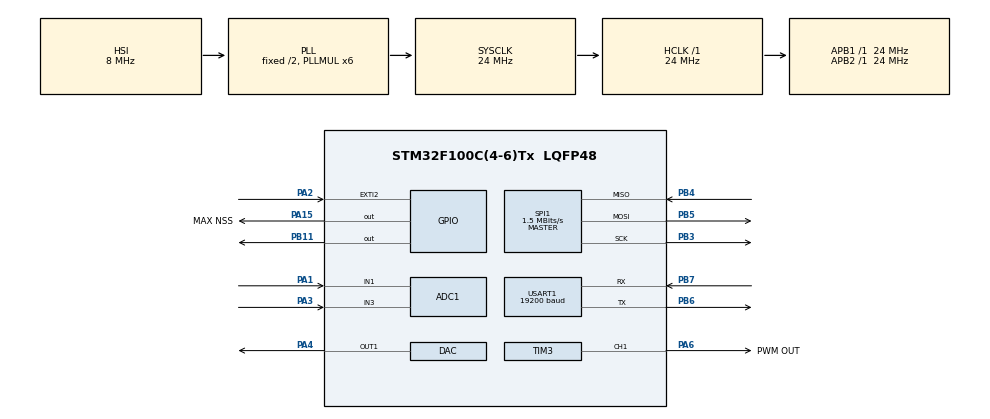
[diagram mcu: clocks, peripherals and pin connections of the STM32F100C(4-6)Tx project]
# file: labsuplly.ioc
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ADC1.Channel-17\#ChannelRegularConversion=ADC_CHANNEL_1
ADC1.Channel-18\#ChannelRegularConversion=ADC_CHANNEL_3
ADC1.ContinuousConvMode=ENABLE
ADC1.DataAlign=ADC_DATAALIGN_RIGHT
ADC1.DiscontinuousConvMode=DISABLE
ADC1.EnableAnalogWatchDog=false
ADC1.EnableRegularConversion=ENABLE
ADC1.ExternalTrigConvEdgeChoice=NONE
ADC1.InjNumberOfConversion=0
ADC1.NbrOfConversion=2
ADC1.NbrOfConversionFlag=1
ADC1.Rank-17\#ChannelRegularConversion=1
ADC1.Rank-18\#ChannelRegularConversion=2
ADC1.SamplingTime-17\#ChannelRegularConversion=ADC_SAMPLETIME_1CYCLE_5
ADC1.SamplingTime-18\#ChannelRegularConversion=ADC_SAMPLETIME_7CYCLES_5
ADC1.ScanConvMode=ADC_SCAN_ENABLE
ADC1.master=1
DAC.DAC_OutputBuffer=DAC_OUTPUTBUFFER_DISABLE
Dma.ADC1.0.Direction=DMA_PERIPH_TO_MEMORY
Dma.ADC1.0.Instance=DMA1_Channel1
Dma.ADC1.0.MemDataAlignment=DMA_MDATAALIGN_WORD
Dma.ADC1.0.MemInc=DMA_MINC_ENABLE
Dma.ADC1.0.Mode=DMA_NORMAL
Dma.ADC1.0.PeriphDataAlignment=DMA_PDATAALIGN_WORD
Dma.ADC1.0.PeriphInc=DMA_PINC_DISABLE
Dma.ADC1.0.Priority=DMA_PRIORITY_MEDIUM
Dma.Request0=ADC1
Dma.Request1=USART1_RX
Dma.Request2=USART1_TX
Dma.USART1_RX.1.Direction=DMA_PERIPH_TO_MEMORY
Dma.USART1_RX.1.Instance=DMA1_Channel5
Dma.USART1_RX.1.MemDataAlignment=DMA_MDATAALIGN_BYTE
Dma.USART1_RX.1.MemInc=DMA_MINC_ENABLE
Dma.USART1_RX.1.Mode=DMA_NORMAL
Dma.USART1_RX.1.PeriphDataAlignment=DMA_PDATAALIGN_BYTE
Dma.USART1_RX.1.PeriphInc=DMA_PINC_DISABLE
Dma.USART1_RX.1.Priority=DMA_PRIORITY_LOW
Dma.USART1_TX.2.Direction=DMA_MEMORY_TO_PERIPH
Dma.USART1_TX.2.Instance=DMA1_Channel4
Dma.USART1_TX.2.MemDataAlignment=DMA_MDATAALIGN_BYTE
Dma.USART1_TX.2.MemInc=DMA_MINC_ENABLE
Dma.USART1_TX.2.Mode=DMA_NORMAL
Dma.USART1_TX.2.PeriphDataAlignment=DMA_PDATAALIGN_BYTE
Dma.USART1_TX.2.PeriphInc=DMA_PINC_DISABLE
Dma.USART1_TX.2.Priority=DMA_PRIORITY_LOW
Mcu.Family=STM32F1
Mcu.Name=STM32F100C(4-6)Tx
Mcu.Package=LQFP48
NVIC.DMA1_Channel1_IRQn=true\:12\:0\:true\:false\:true
NVIC.DMA1_Channel4_IRQn=true\:13\:0\:true\:false\:true
NVIC.DMA1_Channel5_IRQn=true\:14\:0\:true\:false\:true
NVIC.EXTI2_IRQn=true\:1\:0\:true\:false\:true
NVIC.PriorityGroup=NVIC_PRIORITYGROUP_4
NVIC.SPI1_IRQn=true\:10\:0\:true\:false\:true
NVIC.TIM2_IRQn=true\:11\:0\:true\:false\:true
PA1.Signal=ADCx_IN1
PA13.Mode=Serial_Wire
PA13.Signal=SYS_JTMS-SWDIO
PA14.Mode=Serial_Wire
PA14.Signal=SYS_JTCK-SWCLK
PA15.GPIO_Label=MAX NSS
PA15.GPIO_Speed=GPIO_SPEED_FREQ_MEDIUM
PA15.PinState=GPIO_PIN_SET
PA15.Signal=GPIO_Output
PA2.GPIO_PuPd=GPIO_PULLUP
PA2.Signal=GPXTI2
PA3.Signal=ADCx_IN3
PA4.Signal=COMP_DAC1_group
PA6.GPIO_Label=PWM OUT
PA6.GPIO_Speed=GPIO_SPEED_FREQ_LOW
PA6.Signal=S_TIM3_CH1
PB11.GPIO_ModeDefaultOutputPP=GPIO_MODE_OUTPUT_OD
PB11.PinState=GPIO_PIN_SET
PB11.Signal=GPIO_Output
PB3.GPIO_Speed=GPIO_SPEED_FREQ_LOW
PB3.Mode=Full_Duplex_Master
PB3.Signal=SPI1_SCK
PB4.GPIO_PuPd=GPIO_PULLDOWN
PB4.Mode=Full_Duplex_Master
PB4.Signal=SPI1_MISO
PB5.GPIO_Speed=GPIO_SPEED_FREQ_LOW
PB5.Mode=Full_Duplex_Master
PB5.Signal=SPI1_MOSI
PB6.Mode=Asynchronous
PB6.Signal=USART1_TX
PB7.GPIO_PuPd=GPIO_PULLUP
PB7.Mode=Asynchronous
PB7.Signal=USART1_RX
ProjectManager.HeapSize=0x200
ProjectManager.StackSize=0x400
ProjectManager.TargetToolchain=TrueSTUDIO
RCC.AHBFreq_Value=24000000
RCC.APB1Freq_Value=24000000
RCC.APB1TimFreq_Value=24000000
RCC.APB2Freq_Value=24000000
RCC.APB2TimFreq_Value=24000000
RCC.HCLKFreq_Value=24000000
RCC.PLLMUL=RCC_PLL_MUL6
RCC.SYSCLKFreq_VALUE=24000000
RCC.SYSCLKSource=RCC_SYSCLKSOURCE_PLLCLK
SH.ADCx_IN1.0=ADC1_IN1,IN1
SH.ADCx_IN3.0=ADC1_IN3,IN3
SH.COMP_DAC1_group.0=DAC_OUT1,DAC_OUT1
SH.S_TIM3_CH1.0=TIM3_CH1,PWM Generation1 CH1
SPI1.BaudRatePrescaler=SPI_BAUDRATEPRESCALER_16
SPI1.CalculateBaudRate=1.5 MBits/s
SPI1.DataSize=SPI_DATASIZE_16BIT
SPI1.Mode=SPI_MODE_MASTER
TIM2.Period=2399
TIM2.Prescaler=9
TIM3.Period=3399
USART1.BaudRate=19200
VP_TIM2_VS_ClockSourceINT.Mode=Internal
VP_TIM3_VS_ClockSourceINT.Mode=Internal
board=labsuplly

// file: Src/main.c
/**
  ******************************************************************************
  * File Name          : main.c
  * Description        : Main program body
  ******************************************************************************
  *
  * COPYRIGHT(c) 2016 STMicroelectronics
  *
  * Redistribution and use in source and binary forms, with or without modification,
  * are permitted provided that the following conditions are met:
  *   1. Redistributions of source code must retain the above copyright notice,
  *      this list of conditions and the following disclaimer.
  *   2. Redistributions in binary form must reproduce the above copyright notice,
  *      this list of conditions and the following disclaimer in the documentation
  *      and/or other materials provided with the distribution.
  *   3. Neither the name of STMicroelectronics nor the names of its contributors
  *      may be used to endorse or promote products derived from this software
  *      without specific prior written permission.
  *
  * THIS SOFTWARE IS PROVIDED BY THE COPYRIGHT HOLDERS AND CONTRIBUTORS "AS IS"
  * AND ANY EXPRESS OR IMPLIED WARRANTIES, INCLUDING, BUT NOT LIMITED TO, THE
  * IMPLIED WARRANTIES OF MERCHANTABILITY AND FITNESS FOR A PARTICULAR PURPOSE ARE
  * DISCLAIMED. IN NO EVENT SHALL THE COPYRIGHT HOLDER OR CONTRIBUTORS BE LIABLE
  * FOR ANY DIRECT, INDIRECT, INCIDENTAL, SPECIAL, EXEMPLARY, OR CONSEQUENTIAL
  * DAMAGES (INCLUDING, BUT NOT LIMITED TO, PROCUREMENT OF SUBSTITUTE GOODS OR
  * SERVICES; LOSS OF USE, DATA, OR PROFITS; OR BUSINESS INTERRUPTION) HOWEVER
  * CAUSED AND ON ANY THEORY OF LIABILITY, WHETHER IN CONTRACT, STRICT LIABILITY,
  * OR TORT (INCLUDING NEGLIGENCE OR OTHERWISE) ARISING IN ANY WAY OUT OF THE USE
  * OF THIS SOFTWARE, EVEN IF ADVISED OF THE POSSIBILITY OF SUCH DAMAGE.
  *
  ******************************************************************************
  */
#include "stm32f1xx_hal.h"
#include "adc.h"
#include "dac.h"
#include "dma.h"
#include "spi.h"
#include "tim.h"
#include "usart.h"
#include "gpio.h"

void SystemClock_Config(void);

/* USER CODE BEGIN PFP */
/* Private function prototypes -----------------------------------------------*/

/* USER CODE END PFP */

int main(void)
{

  /* MCU Configuration----------------------------------------------------------*/

  /* Reset of all peripherals, Initializes the Flash interface and the Systick. */
  HAL_Init();

  /* Configure the system clock */
  SystemClock_Config();

  /* Initialize all configured peripherals */
  MX_GPIO_Init();
  MX_DMA_Init();
  MX_TIM3_Init();
  MX_ADC1_Init();
  MX_SPI1_Init();
  MX_TIM2_Init();
  MX_USART1_UART_Init();
  MX_DAC_Init();

  /* Infinite loop */
  while (1)
  {

  /* USER CODE BEGIN 3 */

	  ApplicationMain();
	  //user code
  }
  /* USER CODE END 3 */

}

/** System Clock Configuration
*/
void SystemClock_Config(void)
{

  RCC_OscInitTypeDef RCC_OscInitStruct;
  RCC_ClkInitTypeDef RCC_ClkInitStruct;
  RCC_PeriphCLKInitTypeDef PeriphClkInit;

  RCC_OscInitStruct.OscillatorType = RCC_OSCILLATORTYPE_HSI;
  RCC_OscInitStruct.HSIState = RCC_HSI_ON;
  RCC_OscInitStruct.HSICalibrationValue = 16;
  RCC_OscInitStruct.PLL.PLLState = RCC_PLL_ON;
  RCC_OscInitStruct.PLL.PLLSource = RCC_PLLSOURCE_HSI_DIV2;
  RCC_OscInitStruct.PLL.PLLMUL = RCC_PLL_MUL6;
  HAL_RCC_OscConfig(&RCC_OscInitStruct);

  RCC_ClkInitStruct.ClockType = RCC_CLOCKTYPE_HCLK|RCC_CLOCKTYPE_SYSCLK
                              |RCC_CLOCKTYPE_PCLK1|RCC_CLOCKTYPE_PCLK2;
  RCC_ClkInitStruct.SYSCLKSource = RCC_SYSCLKSOURCE_PLLCLK;
  RCC_ClkInitStruct.AHBCLKDivider = RCC_SYSCLK_DIV1;
  RCC_ClkInitStruct.APB1CLKDivider = RCC_HCLK_DIV1;
  RCC_ClkInitStruct.APB2CLKDivider = RCC_HCLK_DIV1;
  HAL_RCC_ClockConfig(&RCC_ClkInitStruct, FLASH_LATENCY_0);

  PeriphClkInit.PeriphClockSelection = RCC_PERIPHCLK_ADC;
  PeriphClkInit.AdcClockSelection = RCC_ADCPCLK2_DIV2;
  HAL_RCCEx_PeriphCLKConfig(&PeriphClkInit);

  HAL_SYSTICK_Config(HAL_RCC_GetHCLKFreq()/1000);

  HAL_SYSTICK_CLKSourceConfig(SYSTICK_CLKSOURCE_HCLK);

  /* SysTick_IRQn interrupt configuration */
  HAL_NVIC_SetPriority(SysTick_IRQn, 0, 0);
}

/************************ (C) COPYRIGHT STMicroelectronics *****END OF FILE****/
